# soc register map
Vendor: litex
Litex SoC 2023-07-09 21:06:10
Registers are 32-bit, read-write, reset 0x0 unless marked. A register's access mark holds for its fields unless they carry their own. Offsets are from the block's base; lines under a group give offsets from that group; [hi:lo] are bit positions; {n}, {i} and the like mark numbered series; 'fields as' and 'values as' point back to an identical list; <NAME> marks a mode.

## Memory map
0x40080000 GPIO size 0x4
0x40082000 UART size 0x20
0x40084000 CONSOLE size 0x20
0x40086000 APP_UART size 0x20
0x40087000 IDENTIFIER_MEM size 0x4
0x40088000 MAIN size 0x20

## Interrupts
0 uart (UART)
1 console (CONSOLE)
2 app_uart (APP_UART)

## Further device data
memoryRegions:
  RERAM baseAddress=0x60000000 size=0x00400000
  SRAM baseAddress=0x61000000 size=0x00200000
  XIP baseAddress=0x70000000 size=0x08000000
  VEXRISCV_DEBUG baseAddress=0xEFFF0000 size=0x00001000
  CSR baseAddress=0x40080000 size=0x00040000
constants:
  CONFIG_CLOCK_FREQUENCY value=800000000
  CONFIG_CPU_TYPE_NONE value=None
  CONFIG_CPU_VARIANT_STANDARD value=None
  CONFIG_CPU_HUMAN_NAME value=Unknown
  CONFIG_BIOS_NO_BUILD_TIME value=None
  CONFIG_CSR_DATA_WIDTH value=32
  CONFIG_CSR_ALIGNMENT value=32
  CONFIG_BUS_STANDARD value=AXI-LITE
  CONFIG_BUS_DATA_WIDTH value=32
  CONFIG_BUS_ADDRESS_WIDTH value=32
  CONFIG_BUS_BURSTING value=0
  APP_UART_INTERRUPT value=2
  CONSOLE_INTERRUPT value=1
  UART_INTERRUPT value=0

## GPIO
Base 0x40080000
0x00 UARTSEL — Used to select which UART is routed to physical pins, 00 = kernel debug, 01 = console, others reserved based on build
  [1:0] uartsel

## UART
Base 0x40082000
Same registers: CONSOLE 0x40084000, APP_UART 0x40086000
0x00 RXTX
  [7:0] rxtx
0x04 TXFULL — TX FIFO Full.
  [0] txfull
0x08 RXEMPTY — RX FIFO Empty.
  [0] rxempty
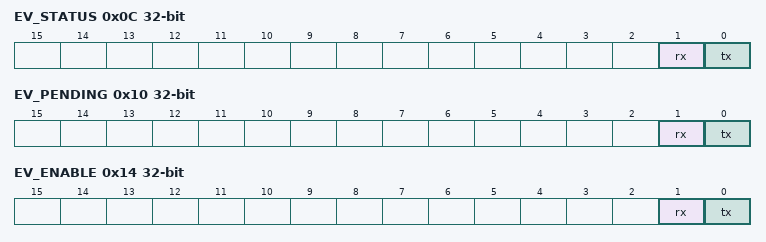
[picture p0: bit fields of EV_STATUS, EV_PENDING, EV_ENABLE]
0x0C EV_STATUS — This register contains the current raw level of the rx event trigger. Writes to this register have no effect.
  [1] rx — Level of the ``rx`` event
  [0] tx — Level of the ``tx`` event
0x10 EV_PENDING — When a rx event occurs, the corresponding bit will be set in this register. To clear the Event, set the corresponding bit in this register.
  [1] rx — `1` if a `rx` event occurred. This Event is triggered on a **falling** edge.
  [0] tx — `1` if a `tx` event occurred. This Event is triggered on a **falling** edge.
0x14 EV_ENABLE — This register enables the corresponding rx events. Write a ``0`` to this register to disable individual events.
  [1] rx — Write a ``1`` to enable the ``rx`` Event
  [0] tx — Write a ``1`` to enable the ``tx`` Event
0x18 TXEMPTY — TX FIFO Empty.
  [0] txempty
0x1C RXFULL — RX FIFO Full.
  [0] rxfull

## IDENTIFIER_MEM
Base 0x40087000
0x00 IDENTIFIER_MEM — 8 x 24-bit memory
  [7:0] identifier_mem

## MAIN
Base 0x40088000
0x00 REPORT — A 32-bit value to report sim state
0x04 SUCCESS — Determines the result code for the simulation. 0 means fail, 1 means pass
  [0] success
0x08 DONE — Set to `1` if the simulation should auto-terminate
  [0] done
0x0C WDATA — Write values here to check cache coherence issues
0x10 RDATA — Data readback derived from coherence_w
0x14 RINC — Every time this is read, the base value is incremented by 3
0x18 IRQTEST0
  [19:0] trigger — Triggers for interrupt testing bank 0
0x1C IRQTEST1
  [19:0] trigger — Triggers for interrupt testing bank 0
